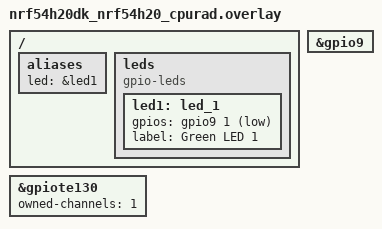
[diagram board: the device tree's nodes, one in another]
/*
 * Copyright (c) 2025 Nordic Semiconductor ASA
 *
 * SPDX-License-Identifier: LicenseRef-Nordic-5-Clause
 */

/ {
	aliases {
		led = &led1;
	};

	leds {
		compatible = "gpio-leds";

		/*
		 * Lilium pulls GPIOs up during bootup, to adapt
		 * to measurement methods, logic is inverted
		 */
		led1: led_1 {
			gpios = <&gpio9 1 GPIO_ACTIVE_LOW>;
			label = "Green LED 1";
		};
	};
};

&gpio9 {
	status = "okay";
};

&gpiote130 {
	status = "okay";
	owned-channels = <1>;
};
